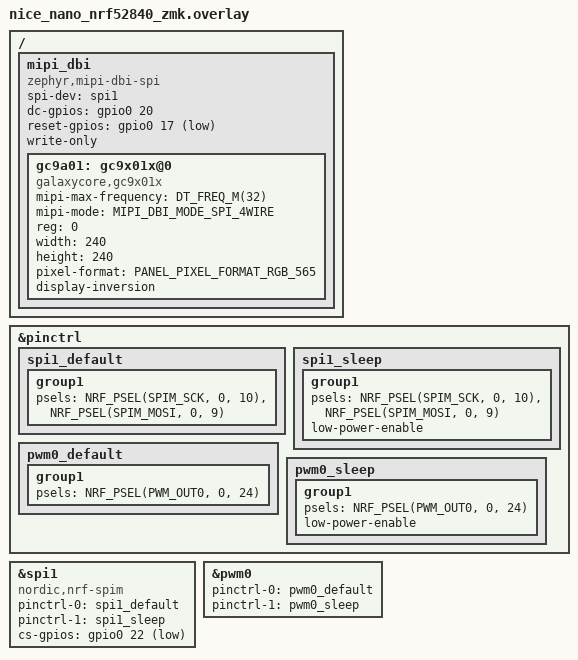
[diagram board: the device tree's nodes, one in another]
/*
 * Zyra FT - per-board overlay dla nice!nano v2
 *
 * Dla dongle: aktywuje SPI1 + GC9A01 + PWM backlight
 * Dla peripherals (lewa/prawa): nieaktywne (dongle node nie istnieje w ich devicetree)
 */

#include <zephyr/dt-bindings/mipi_dbi/mipi_dbi.h>
#include <zephyr/dt-bindings/display/panel.h>

&pinctrl {
    spi1_default: spi1_default {
        group1 {
            psels = <NRF_PSEL(SPIM_SCK, 0, 10)>,
                    <NRF_PSEL(SPIM_MOSI, 0, 9)>;
        };
    };

    spi1_sleep: spi1_sleep {
        group1 {
            psels = <NRF_PSEL(SPIM_SCK, 0, 10)>,
                    <NRF_PSEL(SPIM_MOSI, 0, 9)>;
            low-power-enable;
        };
    };

    pwm0_default: pwm0_default {
        group1 {
            psels = <NRF_PSEL(PWM_OUT0, 0, 24)>;
        };
    };

    pwm0_sleep: pwm0_sleep {
        group1 {
            psels = <NRF_PSEL(PWM_OUT0, 0, 24)>;
            low-power-enable;
        };
    };
};

&spi1 {
    status = "okay";
    compatible = "nordic,nrf-spim";
    pinctrl-0 = <&spi1_default>;
    pinctrl-1 = <&spi1_sleep>;
    pinctrl-names = "default", "sleep";
    cs-gpios = <&gpio0 22 GPIO_ACTIVE_LOW>;
};

/ {
    mipi_dbi {
        compatible = "zephyr,mipi-dbi-spi";
        spi-dev = <&spi1>;
        dc-gpios = <&gpio0 20 GPIO_ACTIVE_HIGH>;
        reset-gpios = <&gpio0 17 GPIO_ACTIVE_LOW>;
        write-only;
        #address-cells = <1>;
        #size-cells = <0>;

        gc9a01: gc9x01x@0 {
            compatible = "galaxycore,gc9x01x";
            mipi-max-frequency = <DT_FREQ_M(32)>;
            mipi-mode = <MIPI_DBI_MODE_SPI_4WIRE>;
            reg = <0>;
            width = <240>;
            height = <240>;
            pixel-format = <PANEL_PIXEL_FORMAT_RGB_565>;
            display-inversion;
        };
    };
};

&pwm0 {
    status = "okay";
    pinctrl-0 = <&pwm0_default>;
    pinctrl-1 = <&pwm0_sleep>;
    pinctrl-names = "default", "sleep";
};
